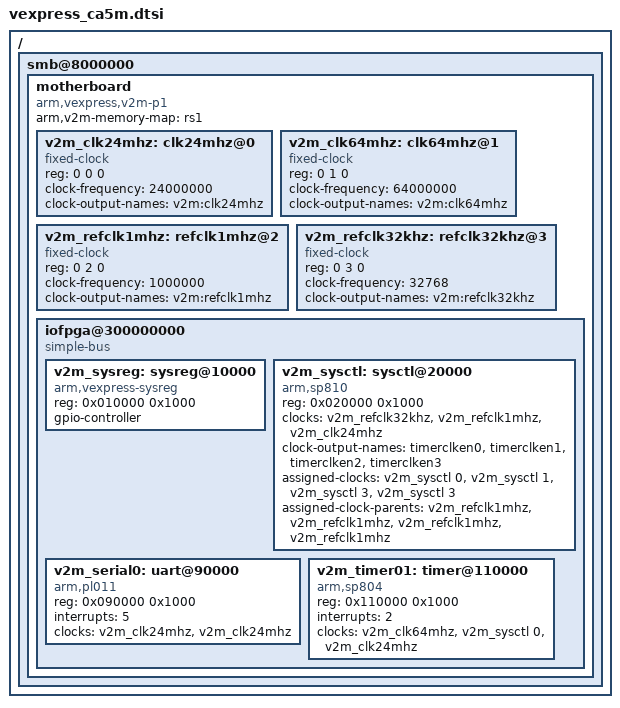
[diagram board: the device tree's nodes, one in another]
/*
 * SPDX-License-Identifier: Apache-2.0
 * Copyright (c) 2019 KapaXL (kapa.xl@outlook.com)
 *
 * FVP Motherboard component
 */

/ {
	smb@8000000 {
		motherboard {
			arm,v2m-memory-map = "rs1";
			compatible = "arm,vexpress,v2m-p1", "simple-bus";
			#address-cells = <2>;
			#size-cells = <1>;
			ranges;

			v2m_clk24mhz: clk24mhz@0 {
				compatible = "fixed-clock";
				#clock-cells = <0>;
				reg = <0 0 0>;
				clock-frequency = <24000000>;
				clock-output-names = "v2m:clk24mhz";
			};

			v2m_clk64mhz: clk64mhz@1 {
				compatible = "fixed-clock";
				#clock-cells = <0>;
				reg = <0 1 0>;
				clock-frequency = <64000000>;
				clock-output-names = "v2m:clk64mhz";
			};

			v2m_refclk1mhz: refclk1mhz@2 {
				compatible = "fixed-clock";
				#clock-cells = <0>;
				reg = <0 2 0>;
				clock-frequency = <1000000>;
				clock-output-names = "v2m:refclk1mhz";
			};

			v2m_refclk32khz: refclk32khz@3 {
				compatible = "fixed-clock";
				#clock-cells = <0>;
				reg = <0 3 0>;
				clock-frequency = <32768>;
				clock-output-names = "v2m:refclk32khz";
			};

			iofpga@300000000 {
				compatible = "simple-bus";
				#address-cells = <1>;
				#size-cells = <1>;
				ranges = <0 3 0 0x200000>;

				v2m_sysreg: sysreg@10000 {
					compatible = "arm,vexpress-sysreg";
					reg = <0x010000 0x1000>;
					gpio-controller;
					#gpio-cells = <2>;
				};

				v2m_sysctl: sysctl@20000 {
					compatible = "arm,sp810", "arm,primecell";
					reg = <0x020000 0x1000>;
					clocks = <&v2m_refclk32khz>, <&v2m_refclk1mhz>, <&v2m_clk24mhz>;
					clock-names = "refclk", "timclk", "apb_pclk";
					#clock-cells = <1>;
					clock-output-names = "timerclken0", "timerclken1", "timerclken2", "timerclken3";
					assigned-clocks = <&v2m_sysctl 0>, <&v2m_sysctl 1>, <&v2m_sysctl 3>, <&v2m_sysctl 3>;
					assigned-clock-parents = <&v2m_refclk1mhz>, <&v2m_refclk1mhz>, <&v2m_refclk1mhz>, <&v2m_refclk1mhz>;
				};

				v2m_serial0: uart@90000 {
					compatible = "arm,pl011", "arm,primecell";
					reg = <0x090000 0x1000>;
					interrupts = <5>;
					clocks = <&v2m_clk24mhz>, <&v2m_clk24mhz>;
					clock-names = "uartclk", "apb_pclk";
				};

				v2m_timer01: timer@110000 {
					compatible = "arm,sp804", "arm,primecell";
					reg = <0x110000 0x1000>;
					interrupts = <2>;
					clocks = <&v2m_clk64mhz>, <&v2m_sysctl 0>, <&v2m_clk24mhz>;
					clock-names = "timclken1", "timclken2", "apb_pclk";
				};
			};
		};
	};
};
